# PIC32CM1602GV00032 register map
Vendor: Microchip Technology; Series: PIC32CMGV00; File version: 0
CPU: CM0+ r0p0, little endian, no MPU, no FPU, VTOR, 2 interrupt priority bits, 25 interrupts
Registers are 8-bit, read-write, reset 0x0 unless marked. A register's access mark holds for its fields unless they carry their own. Offsets are from the block's base; [hi:lo] are bit positions; 'fields as' and 'values as' point back to an identical list.

## NVMCTRL — Non-Volatile Memory Controller
Base 0x41004000
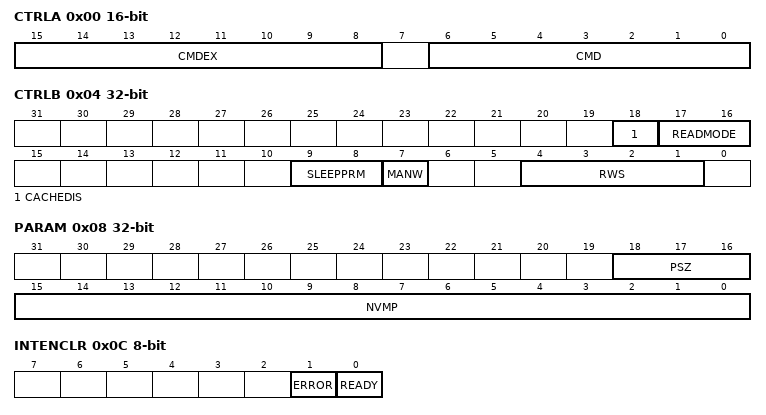
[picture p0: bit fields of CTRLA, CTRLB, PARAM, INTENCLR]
0x00 CTRLA 16-bit — Control A
  [15:8] CMDEX — Command Execution
    165=KEY (Execution Key)
  [6:0] CMD — Command
    2=ER (Erase Row - Erases the row addressed by the ADDR register.); 4=WP (Write Page - Writes the contents of the page buffer to the page addressed by the ADDR register.); 5=EAR (Erase Auxiliary Row - Erases the auxiliary row addressed by the ADDR register. This command can be given only when the security bit is not set and only to the user configuration row.); 6=WAP (Write Auxiliary Page - Writes the contents of the page buffer to the page addressed by the ADDR register. This command can be given only when the security bit is not set and only to the user configuration row.); 10=SF (Security Flow Command); 15=WL (Write lockbits); 64=LR (Lock Region - Locks the region containing the address location in the ADDR register.); 65=UR (Unlock Region - Unlocks the region containing the address location in the ADDR register.); 66=SPRM (Sets the power reduction mode.); 67=CPRM (Clears the power reduction mode.); 68=PBC (Page Buffer Clear - Clears the page buffer.); 69=SSB (Set Security Bit - Sets the security bit by writing 0x00 to the first byte in the lockbit row.); 70=INVALL (Invalidate all cache lines.)
0x04 CTRLB 32-bit — Control B
  [18] CACHEDIS — Cache Disable
  [17:16] READMODE — NVMCTRL Read Mode
    0=NO_MISS_PENALTY (The NVM Controller (cache system) does not insert wait states on a cache miss. Gives the best system performance.); 1=LOW_POWER (Reduces power consumption of the cache system, but inserts a wait state each time there is a cache miss. This mode may not be relevant if CPU performance is required, as the application will be stalled and may lead to increase run time.); 2=DETERMINISTIC (The cache system ensures that a cache hit or miss takes the same amount of time, determined by the number of programmed flash wait states. This mode can be used for real-time applications that require deterministic execution timings.)
  [9:8] SLEEPPRM — Power Reduction Mode during Sleep
    0=WAKEONACCESS (NVM block enters low-power mode when entering sleep.NVM block exits low-power mode upon first access.); 1=WAKEUPINSTANT (NVM block enters low-power mode when entering sleep.NVM block exits low-power mode when exiting sleep.); 3=DISABLED (Auto power reduction disabled.)
  [7] MANW — Manual Write
  [4:1] RWS — NVM Read Wait States
    0=SINGLE (Single Auto Wait State); 1=HALF (Half Auto Wait State); 2=DUAL (Dual Auto Wait State)
0x08 PARAM 32-bit — NVM Parameter
  [18:16] PSZ — Page Size
    0=8 bytes; 1=16 bytes; 2=32 bytes; 3=64 bytes; 4=128 bytes; 5=256 bytes; 6=512 bytes; 7=1024 bytes
  [15:0] NVMP — NVM Pages
0x0C INTENCLR write-1-clears — Interrupt Enable Clear
  [1] ERROR — Error Interrupt Enable
  [0] READY — NVM Ready Interrupt Enable
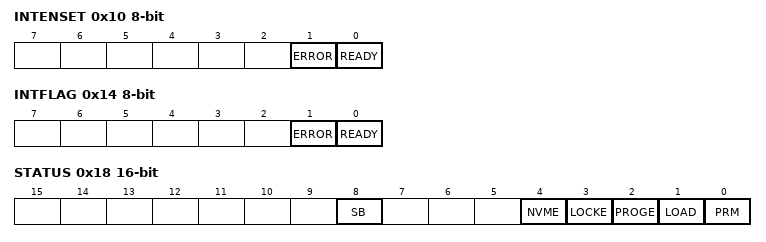
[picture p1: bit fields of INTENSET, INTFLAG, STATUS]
0x10 INTENSET write-1-sets — Interrupt Enable Set
  fields as INTENCLR
0x14 INTFLAG write-1-clears — Interrupt Flag Status and Clear
  [1] ERROR
  [0] READY — NVM Ready
0x18 STATUS 16-bit
  [8] SB — Security Bit Status
  [4] NVME — NVM Error
  [3] LOCKE — Lock Error Status
  [2] PROGE — Programming Error Status
  [1] LOAD — NVM Page Buffer Active Loading
  [0] PRM — Power Reduction Mode
0x1C ADDR 32-bit — Address
  [21:0] ADDR — NVM Address
0x20 LOCK 16-bit — Lock Section
  [15:0] LOCK — Region Lock Bits

## PAC0 — Peripheral Access Controller
Base 0x40000000; register names take the prefix PAC_
Same registers: PAC1 0x41000000, PAC2 0x42000000
0x00 WPCLR 32-bit write-1-clears — Write Protection Clear
  [31:1] WP
0x04 WPSET 32-bit write-1-sets — Write Protection Set
  [31:1] WP

## Notices in the file
Copyright (c) 2026 Microchip Technology Inc.
SPDX-License-Identifier: Apache-2.0
Licensed under the Apache License, Version 2.0 (the "License");
you may not use this file except in compliance with the License.
You may obtain a copy of the License at
http://www.apache.org/licenses/LICENSE-2.0
Unless required by applicable law or agreed to in writing, software
distributed under the License is distributed on an "AS IS" BASIS,
WITHOUT WARRANTIES OR CONDITIONS OF ANY KIND, either express or implied.
See the License for the specific language governing permissions and
limitations under the License.
